CM_ "IMPORT _bosch_2021.dbc";

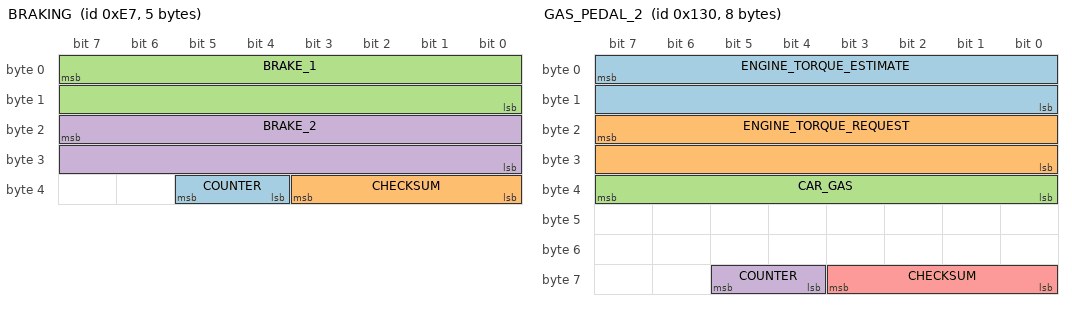
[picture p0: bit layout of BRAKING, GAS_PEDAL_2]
BO_ 231 BRAKING: 5 XXX
 SG_ COUNTER : 37|2@0+ (1,0) [0|3] "" XXX
 SG_ CHECKSUM : 35|4@0+ (1,0) [0|15] "" XXX
 SG_ BRAKE_1 : 7|16@0+ (1,0) [0|255] "" XXX
 SG_ BRAKE_2 : 23|16@0+ (1,0) [0|65535] "" XXX

BO_ 304 GAS_PEDAL_2: 8 PCM
 SG_ ENGINE_TORQUE_ESTIMATE : 7|16@0- (1,0) [-1000|1000] "Nm" EON
 SG_ ENGINE_TORQUE_REQUEST : 23|16@0- (1,0) [-1000|1000] "Nm" EON
 SG_ CAR_GAS : 39|8@0+ (1,0) [0|255] "" EON
 SG_ COUNTER : 61|2@0+ (1,0) [0|3] "" EON
 SG_ CHECKSUM : 59|4@0+ (1,0) [0|15] "" EON

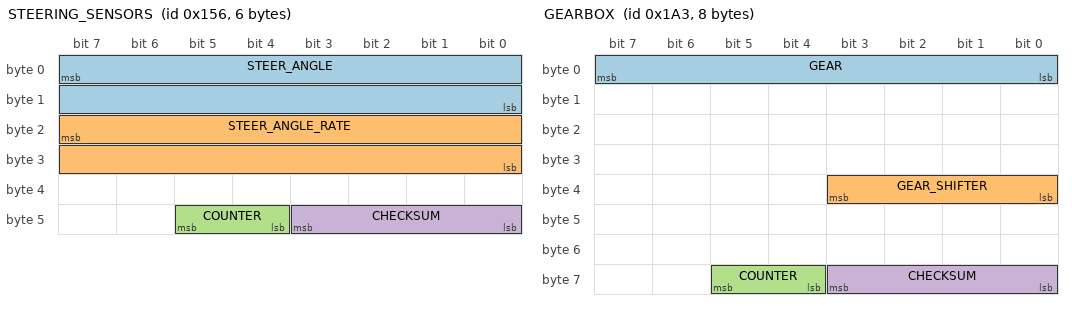
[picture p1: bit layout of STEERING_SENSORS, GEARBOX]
BO_ 342 STEERING_SENSORS: 6 EPS
 SG_ STEER_ANGLE : 7|16@0- (-0.1,0) [-500|500] "deg" EON
 SG_ STEER_ANGLE_RATE : 23|16@0- (1,0) [-3000|3000] "deg/s" EON
 SG_ COUNTER : 45|2@0+ (1,0) [0|3] "" EON
 SG_ CHECKSUM : 43|4@0+ (1,0) [0|3] "" EON

BO_ 419 GEARBOX: 8 PCM
 SG_ GEAR : 7|8@0+ (1,0) [0|256] "" EON
 SG_ GEAR_SHIFTER : 35|4@0+ (1,0) [0|15] "" EON
 SG_ COUNTER : 61|2@0+ (1,0) [0|3] "" EON
 SG_ CHECKSUM : 59|4@0+ (1,0) [0|3] "" EON

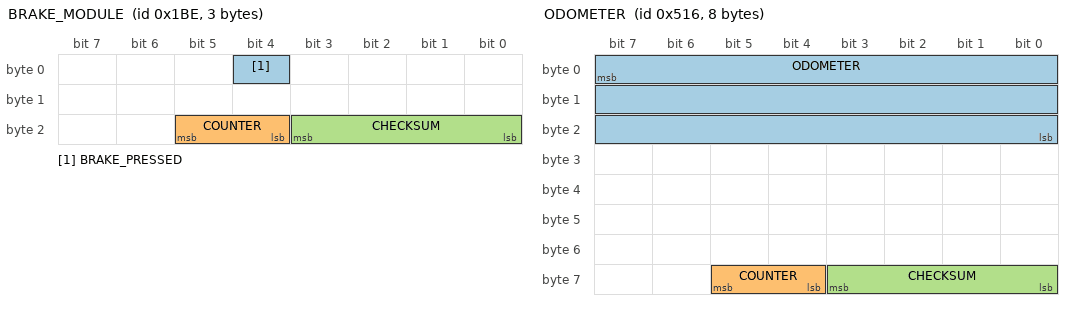
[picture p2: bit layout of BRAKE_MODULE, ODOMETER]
BO_ 446 BRAKE_MODULE: 3 VSA
 SG_ BRAKE_PRESSED : 4|1@0+ (1,0) [0|1] "" XXX
 SG_ COUNTER : 21|2@0+ (1,0) [0|3] "" XXX
 SG_ CHECKSUM : 19|4@0+ (1,0) [0|15] "" XXX

BO_ 927 RADAR_HUD: 8 ADAS
 SG_ ZEROS_BOH : 7|17@0+ (1,0) [0|127] "" BDY
 SG_ APPLY_BRAKES_FOR_CANC : 23|1@0+ (1,0) [0|15] "" BDY
 SG_ ZEROS_BOH2 : 31|8@0+ (1,0) [0|127] "" BDY
 SG_ RESUME_INSTRUCTION : 21|1@0+ (1,0) [0|15] "" BDY
 SG_ ACC_ALERTS : 20|5@0+ (1,0) [0|15] "" BDY
 SG_ LEAD_SPEED : 39|9@0+ (1,0) [0|127] "" BDY
 SG_ LEAD_STATE : 46|3@0+ (1,0) [0|127] "" BDY
 SG_ LEAD_DISTANCE : 43|5@0+ (1,0) [0|31] "" BDY
 SG_ ZEROS_BOH3 : 54|7@0+ (1,0) [0|127] "" BDY
 SG_ COUNTER : 61|2@0+ (1,0) [0|3] "" BDY
 SG_ CHECKSUM : 59|4@0+ (1,0) [0|3] "" BDY

BO_ 1302 ODOMETER: 8 XXX
 SG_ ODOMETER : 7|24@0+ (1,0) [0|16777215] "km" EON
 SG_ COUNTER : 61|2@0+ (1,0) [0|3] "" EON
 SG_ CHECKSUM : 59|4@0+ (1,0) [0|3] "" EON

CM_ SG_ 419 GEAR "10 = reverse, 11 = transition";

VAL_ 419 GEAR_SHIFTER 10 "S" 4 "D" 3 "N" 2 "R" 1 "P" ;
VAL_ 927 ACC_ALERTS 29 "esp_active_acc_canceled" 10 "b_pedal_applied" 9 "speed_too_low" 8 "speed_too_high" 7 "p_brake_applied" 6 "gear_no_d" 5 "seatbelt" 4 "too_steep_downhill" 3 "too_steep_uphill" 2 "too_close" 1 "no_vehicle_ahead" ;

CM_ "CHFFR_METRIC 342 STEER_ANGLE STEER_ANGLE 0.36 180; CHFFR_METRIC 380 ENGINE_RPM ENGINE_RPM 1 0; CHFFR_METRIC 804 ENGINE_TEMPERATURE ENGINE_TEMPERATURE 1 0";
